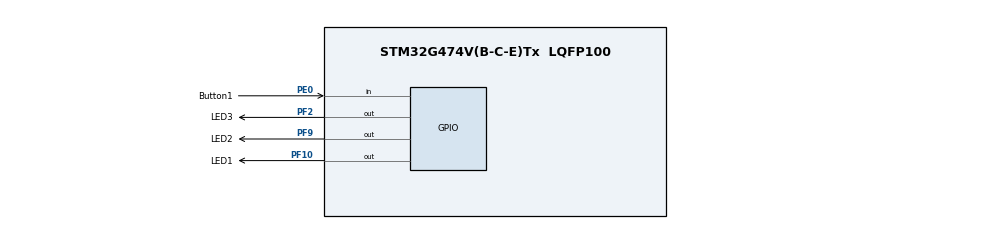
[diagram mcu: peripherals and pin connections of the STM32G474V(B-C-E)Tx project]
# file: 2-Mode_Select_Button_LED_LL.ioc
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Mcu.Family=STM32G4
Mcu.Name=STM32G474V(B-C-E)Tx
Mcu.Package=LQFP100
NVIC.PriorityGroup=NVIC_PRIORITYGROUP_4
PE0.GPIO_Label=Button1
PE0.GPIO_PuPd=GPIO_PULLUP
PE0.Signal=GPIO_Input
PF0-OSC_IN.Mode=HSE-External-Oscillator
PF0-OSC_IN.Signal=RCC_OSC_IN
PF1-OSC_OUT.Mode=HSE-External-Oscillator
PF1-OSC_OUT.Signal=RCC_OSC_OUT
PF10.GPIO_Label=LED1
PF10.GPIO_Speed=GPIO_SPEED_FREQ_MEDIUM
PF10.PinState=GPIO_PIN_SET
PF10.Signal=GPIO_Output
PF2.GPIO_Label=LED3
PF2.GPIO_Speed=GPIO_SPEED_FREQ_MEDIUM
PF2.PinState=GPIO_PIN_SET
PF2.Signal=GPIO_Output
PF9.GPIO_Label=LED2
PF9.GPIO_Speed=GPIO_SPEED_FREQ_MEDIUM
PF9.PinState=GPIO_PIN_SET
PF9.Signal=GPIO_Output
ProjectManager.HeapSize=0x200
ProjectManager.StackSize=0x400
ProjectManager.TargetToolchain=STM32CubeIDE
RCC.AHBFreq_Value=16000000
RCC.APB1Freq_Value=16000000
RCC.APB1TimFreq_Value=16000000
RCC.APB2Freq_Value=16000000
RCC.APB2TimFreq_Value=16000000
RCC.CortexFreq_Value=16000000
RCC.EXTERNAL_CLOCK_VALUE=12288000
RCC.HCLKFreq_Value=16000000
RCC.HSE_VALUE=40000000
RCC.HSI48_VALUE=48000000
RCC.HSI_VALUE=16000000
RCC.LSE_VALUE=32768
RCC.SYSCLKFreq_VALUE=16000000
RCC.USBFreq_Value=64000000
RCC.VCOOutputFreq_Value=128000000
VP_SYS_VS_DBSignals.Mode=DisableDeadBatterySignals
board=custom

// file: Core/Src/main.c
/* USER CODE BEGIN Header */
/**
  ******************************************************************************
  * @file           : main.c
  * @brief          : Main program body
  ******************************************************************************
  * @attention
  *
  * Copyright (c) 2026 STMicroelectronics.
  * All rights reserved.
  *
  * This software is licensed under terms that can be found in the LICENSE file
  * in the root directory of this software component.
  * If no LICENSE file comes with this software, it is provided AS-IS.
  *
  ******************************************************************************
  */
/* USER CODE END Header */
#include "main.h"

void SystemClock_Config(void);
static void MX_GPIO_Init(void);

int main(void)
{

  /* MCU Configuration--------------------------------------------------------*/

  /* Reset of all peripherals, Initializes the Flash interface and the Systick. */
  LL_APB2_GRP1_EnableClock(LL_APB2_GRP1_PERIPH_SYSCFG);
  LL_APB1_GRP1_EnableClock(LL_APB1_GRP1_PERIPH_PWR);

  /* System interrupt init*/
  NVIC_SetPriorityGrouping(NVIC_PRIORITYGROUP_4);

  /* SysTick_IRQn interrupt configuration */
  NVIC_SetPriority(SysTick_IRQn, NVIC_EncodePriority(NVIC_GetPriorityGrouping(),15, 0));

  /** Disable the internal Pull-Up in Dead Battery pins of UCPD peripheral
  */
  LL_PWR_DisableUCPDDeadBattery();

  /* Configure the system clock */
  SystemClock_Config();

  /* Initialize all configured peripherals */
  MX_GPIO_Init();
  /* USER CODE BEGIN 2 */
uint8_t mode = 0;
  /* USER CODE END 2 */

  /* Infinite loop */
  while (1)
  {

    /* USER CODE BEGIN 3 */
	  if (!LL_GPIO_IsInputPinSet(GPIOE, LL_GPIO_PIN_0))
	  {
		  LL_mDelay(50);
		  if(!LL_GPIO_IsInputPinSet(GPIOE, LL_GPIO_PIN_0))
		  {
			  mode++;
			  if(mode > 3) mode = 0;
			  LL_GPIO_SetOutputPin(GPIOF, LL_GPIO_PIN_9 | LL_GPIO_PIN_2 | LL_GPIO_PIN_10);

			  if (mode == 1)  LL_GPIO_ResetOutputPin(GPIOF, LL_GPIO_PIN_9);
			  else if (mode == 2) LL_GPIO_ResetOutputPin(GPIOF, LL_GPIO_PIN_2);
			  else if (mode == 3) LL_GPIO_ResetOutputPin(GPIOF, LL_GPIO_PIN_10);

			  while (!LL_GPIO_IsInputPinSet(GPIOE, LL_GPIO_PIN_0));
		  }
	  }
  }
  /* USER CODE END 3 */
}

void SystemClock_Config(void)
{
  LL_FLASH_SetLatency(LL_FLASH_LATENCY_0);
  while(LL_FLASH_GetLatency() != LL_FLASH_LATENCY_0)
  {
  }
  LL_PWR_SetRegulVoltageScaling(LL_PWR_REGU_VOLTAGE_SCALE1);
  LL_RCC_HSI_Enable();
   /* Wait till HSI is ready */
  while(LL_RCC_HSI_IsReady() != 1)
  {
  }

  LL_RCC_HSI_SetCalibTrimming(64);
  LL_RCC_SetSysClkSource(LL_RCC_SYS_CLKSOURCE_HSI);
   /* Wait till System clock is ready */
  while(LL_RCC_GetSysClkSource() != LL_RCC_SYS_CLKSOURCE_STATUS_HSI)
  {
  }

  /* Set AHB prescaler*/
  LL_RCC_SetAHBPrescaler(LL_RCC_SYSCLK_DIV_1);
  LL_RCC_SetAPB1Prescaler(LL_RCC_APB1_DIV_1);
  LL_RCC_SetAPB2Prescaler(LL_RCC_APB2_DIV_1);

  LL_Init1msTick(16000000);

  LL_SetSystemCoreClock(16000000);
}

static void MX_GPIO_Init(void)
{
  LL_GPIO_InitTypeDef GPIO_InitStruct = {0};

  /* GPIO Ports Clock Enable */
  LL_AHB2_GRP1_EnableClock(LL_AHB2_GRP1_PERIPH_GPIOF);
  LL_AHB2_GRP1_EnableClock(LL_AHB2_GRP1_PERIPH_GPIOE);

  /**/
  LL_GPIO_SetOutputPin(LED2_GPIO_Port, LED2_Pin);

  /**/
  LL_GPIO_SetOutputPin(LED1_GPIO_Port, LED1_Pin);

  /**/
  LL_GPIO_SetOutputPin(LED3_GPIO_Port, LED3_Pin);

  /**/
  GPIO_InitStruct.Pin = LED2_Pin;
  GPIO_InitStruct.Mode = LL_GPIO_MODE_OUTPUT;
  GPIO_InitStruct.Speed = LL_GPIO_SPEED_FREQ_MEDIUM;
  GPIO_InitStruct.OutputType = LL_GPIO_OUTPUT_PUSHPULL;
  GPIO_InitStruct.Pull = LL_GPIO_PULL_NO;
  LL_GPIO_Init(LED2_GPIO_Port, &GPIO_InitStruct);

  /**/
  GPIO_InitStruct.Pin = LED1_Pin;
  GPIO_InitStruct.Mode = LL_GPIO_MODE_OUTPUT;
  GPIO_InitStruct.Speed = LL_GPIO_SPEED_FREQ_MEDIUM;
  GPIO_InitStruct.OutputType = LL_GPIO_OUTPUT_PUSHPULL;
  GPIO_InitStruct.Pull = LL_GPIO_PULL_NO;
  LL_GPIO_Init(LED1_GPIO_Port, &GPIO_InitStruct);

  /**/
  GPIO_InitStruct.Pin = LED3_Pin;
  GPIO_InitStruct.Mode = LL_GPIO_MODE_OUTPUT;
  GPIO_InitStruct.Speed = LL_GPIO_SPEED_FREQ_MEDIUM;
  GPIO_InitStruct.OutputType = LL_GPIO_OUTPUT_PUSHPULL;
  GPIO_InitStruct.Pull = LL_GPIO_PULL_NO;
  LL_GPIO_Init(LED3_GPIO_Port, &GPIO_InitStruct);

  /**/
  GPIO_InitStruct.Pin = Button1_Pin;
  GPIO_InitStruct.Mode = LL_GPIO_MODE_INPUT;
  GPIO_InitStruct.Pull = LL_GPIO_PULL_UP;
  LL_GPIO_Init(Button1_GPIO_Port, &GPIO_InitStruct);

}

void Error_Handler(void)
{
  __disable_irq();
  while (1)
  {
  }
}
